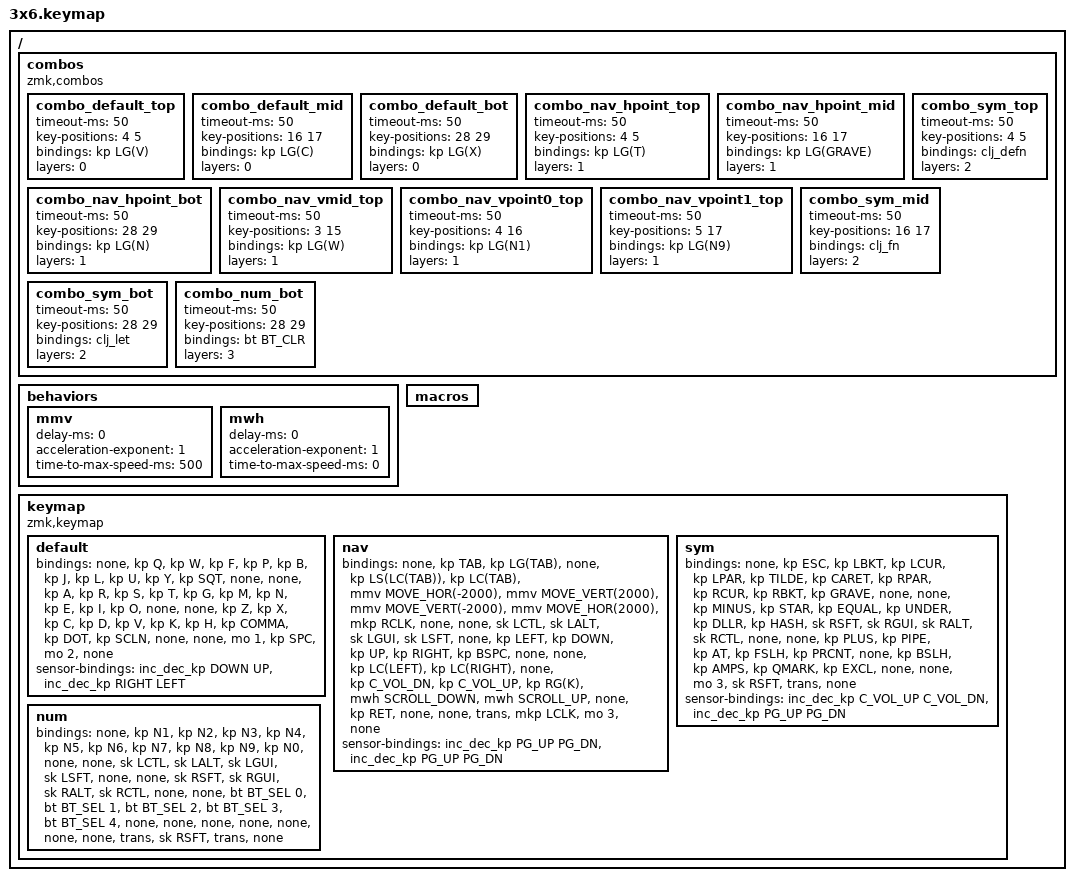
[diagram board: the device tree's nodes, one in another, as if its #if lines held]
#include <behaviors.dtsi>
#include <dt-bindings/zmk/keys.h>
#include <dt-bindings/zmk/mouse.h>
#include <dt-bindings/zmk/bt.h>

/ {
    #include "clojure.dtsi"
    combos {
      // default layer
      compatible = "zmk,combos";
       combo_default_top {
        timeout-ms = <50>;
        key-positions = <4 5>;
        bindings = <&kp LG(V)>; // paste
        layers = <0>;
      };
      combo_default_mid {
        timeout-ms = <50>;
        key-positions = <16 17>;
        bindings = <&kp LG(C)>; // copy
        layers = <0>;
      };
      combo_default_bot {
        timeout-ms = <50>;
        key-positions = <28 29>;
        bindings = <&kp LG(X)>; // cut
        layers = <0>;
      };

      // nav layer
      combo_nav_hpoint_top {
        timeout-ms = <50>;
        key-positions = <4 5>;
        bindings = <&kp LG(T)>; // new tab
        layers = <1>;
      };
      combo_nav_hpoint_mid {
        timeout-ms = <50>;
        key-positions = <16 17>;
        bindings = <&kp LG(GRAVE)>; // switch win
        layers = <1>;
      };
      combo_nav_hpoint_bot {
        timeout-ms = <50>;
        key-positions = <28 29>;
        bindings = <&kp LG(N)>; // new win
        layers = <1>;
      };
      combo_nav_vmid_top {
        timeout-ms = <50>;
        key-positions = <3 15>;
        bindings = <&kp LG(W)>; // close win
        layers = <1>;
      };
      combo_nav_vpoint0_top {
        timeout-ms = <50>;
        key-positions = <4 16>;
        bindings = <&kp LG(N1)>; // first tab
        layers = <1>;
      };
      combo_nav_vpoint1_top {
        timeout-ms = <50>;
        key-positions = <5 17>;
        bindings = <&kp LG(N9)>; // last tab
        layers = <1>;
      };



      // symbol layer
      combo_sym_top {
        timeout-ms = <50>;
        key-positions = <4 5>;
        bindings = <&clj_defn>;
        layers = <2>;
      };
      combo_sym_mid {
        timeout-ms = <50>;
        key-positions = <16 17>;
        bindings = <&clj_fn>;
        layers = <2>;
      };
      combo_sym_bot {
        timeout-ms = <50>;
        key-positions = <28 29>;
        bindings = <&clj_let>;
        layers = <2>;
      };

      // num layer
      combo_num_bot {
        timeout-ms = <50>;
        key-positions = <28 29>;
        bindings = <&bt BT_CLR>;
        layers = <3>;
      };
    };
 
    behaviors {
      mmv {
        delay-ms = <0>;
        acceleration-exponent=<1>;
        time-to-max-speed-ms = <500>;
      };
      mwh {
        delay-ms = <0>;
        acceleration-exponent=<1>;
        time-to-max-speed-ms = <0>;
      };
    };

    macros {
      
    };

        keymap {
                compatible = "zmk,keymap";

                default {
// ---------------------------------------------------------------------------
// |    |  Q  |  W  |  F  |  P  |  B  |   |  J  |  L  |  U  |  Y  |  '  |    |
// |    |  A  |  R  |  S  |  T  |  G  |   |  M  |  N  |  E  |  I  |  O  |    |
// |    |  Z  |  X  |  C  |  D  |  V  |   |  K  |  H  |  ,  |  .  |  ;  |    |
//                        | nav | spc |   | sft | sym |
                        bindings = <
   &none &kp Q &kp W &kp F &kp P &kp B     &kp J &kp L &kp U      &kp Y   &kp SQT  &none
   &none &kp A &kp R &kp S &kp T &kp G     &kp M &kp N &kp E      &kp I   &kp O    &none
   &none &kp Z &kp X &kp C &kp D &kp V     &kp K &kp H &kp COMMA  &kp DOT &kp SCLN &none
   #ifdef FIVETHUMBS
                        &none &mo 1 &kp SPC &mo 2 &none
   #else
                   &none &mo 1 &kp SPC     &kp RSFT &mo 2 &none
   #endif
                        >;
                sensor-bindings = <&inc_dec_kp DOWN UP &inc_dec_kp RIGHT LEFT>;

                };

                nav {
// --------------------------------------------------------------------------------------
// |    |  tab | sapp | tabl | tabr | vlup |   | mlft | mdwn |  mup | mrgt | rclk |    |
// |    | ctrl |  alt |  cmd | shft | vldn |   | left | down |   up | rght | bspc |    |
// |    | spcl | spcr | back | swin | play |   |      | pdwn | pgup | swpl | entr |    |
//                           |      |      |   | lclk |  num |
                        bindings = <
   &none &kp TAB      &kp LG(TAB)   &none    &kp LS(LC(TAB)) &kp LC(TAB)      &mmv MOVE_HOR(-2000) &mmv MOVE_VERT(2000) &mmv MOVE_VERT(-2000) &mmv MOVE_HOR(2000) &mkp RCLK &none
   &none &sk LCTL     &sk LALT      &sk LGUI &sk LSFT        &none            &kp LEFT             &kp DOWN             &kp UP                &kp RIGHT           &kp BSPC  &none
   &none &kp LC(LEFT) &kp LC(RIGHT) &none    &kp C_VOL_DN    &kp C_VOL_UP     &kp RG(K)            &mwh SCROLL_DOWN     &mwh SCROLL_UP        &none               &kp RET   &none
   #ifdef FIVETHUMBS
                                                &none &trans &mkp LCLK &mo 3 &none
   #else
                                            &none &trans &trans     &mkp LCLK &mo 3 &none
   #endif
                       >;
                sensor-bindings = <&inc_dec_kp PG_UP PG_DN &inc_dec_kp PG_UP PG_DN>;
                };

                sym {
// ---------------------------------------------------------------------------
// |    | ESC |  [  |  {  |  (  |  ~  |   |  ^   |  )  |  }  |  ]  |  `  |    |
// |    |  -  |  *  |  =  |  _  |  $  |   |  #  | SFT | CMD | ALT | CTL |    |
// |    |  +  |  |  |  @  |  /  |  %  |   |     |  \  |  &  |  ?  |  !  |    |
//                        |     | ADJ |   |     |     |
                        bindings = <
   &none &kp ESC   &kp LBKT &kp LCUR  &kp LPAR  &kp TILDE     &kp CARET &kp RPAR &kp RCUR &kp RBKT  &kp GRAVE &none
   &none &kp MINUS &kp STAR &kp EQUAL &kp UNDER &kp DLLR      &kp HASH  &sk RSFT &sk RGUI &sk RALT  &sk RCTL  &none
   &none &kp PLUS  &kp PIPE &kp AT    &kp FSLH  &kp PRCNT     &none     &kp BSLH &kp AMPS &kp QMARK &kp EXCL  &none
   #ifdef FIVETHUMBS
                                           &none &mo 3 &sk RSFT &trans &none
   #else
                                       &none &mo 3 &trans     &trans &trans &none
   #endif
                        >;
                sensor-bindings = <&inc_dec_kp C_VOL_UP C_VOL_DN &inc_dec_kp PG_UP PG_DN>;
                };

                num {
// -----------------------------------------------------------------------------
// |    |  1  |  2  |  3  |  4  |  5  |   |   6   |  7  |  8  |  9  |  0  |    |  
// |    | CTL | ALT | GUI | SFT |     |   |       | SFT | GUI | ALT | CTL |    |
// |    | bt0 | bt1 | bt2 | bt3 | bt4 |   | btclr |     |     |     |     |    |
//                        |     |     |   |       |     |
                        bindings = <
   &none &kp N1       &kp N2       &kp N3       &kp N4       &kp N5           &kp N6     &kp N7   &kp N8   &kp N9   &kp N0   &none
   &none &sk LCTL     &sk LALT     &sk LGUI     &sk LSFT     &none            &none      &sk RSFT &sk RGUI &sk RALT &sk RCTL &none
   &none &bt BT_SEL 0 &bt BT_SEL 1 &bt BT_SEL 2 &bt BT_SEL 3 &bt BT_SEL 4     &none      &none    &none    &none    &none    &none
   #ifdef FIVETHUMBS
                                                          &none &trans &sk RSFT &trans &none
   #else
                                                      &none &trans &trans     &trans &trans &none
   #endif
                       >;
                };
        };
};
